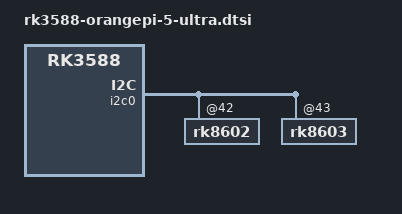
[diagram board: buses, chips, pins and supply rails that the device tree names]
// SPDX-License-Identifier: (GPL-2.0+ OR MIT)
/*
 * PATCHED DTSI – Orange Pi 5 Ultra
 * File: rk3588-orangepi-5-ultra-r06.dtsi
 *
 * Revision note:
 * r06 - keep OPi5U big-cluster 2400 MHz released and overvolted to 1.05 V
 *       only at the final 2400 MHz OPP
 *     - relax big-cluster OPP consumer max ceilings from 1.00 V to 1.05 V
 *       across cluster1 and cluster2 standard OPP tables so transitions from
 *       the 2400 MHz 1.05 V step do not fail on the shared cpu/mem rail vote
 *     - keep lower OPP target/min voltages unchanged
 *     - patch rk8602/rk8603 under &i2c0 to avoid forward-label issues
 *
 * Notes:
 * - This is board-local for OPi5U in FriendlyElec AOSP 14 tree.
 * - Lower big-cluster OPPs are NOT overvolted in target/min terms.
 * - Only their allowed max ceiling is relaxed to match the rail ceiling.
 */

&i2c0 {
	rk8602@42 {
		regulator-max-microvolt = <1050000>;
	};

	rk8603@43 {
		regulator-max-microvolt = <1050000>;
	};
};

&cluster1_opp_table {
	opp-408000000 {
		opp-microvolt = <675000 675000 1050000>,
			       <675000 675000 1050000>;
	};
	opp-600000000 {
		opp-microvolt = <675000 675000 1050000>,
			       <675000 675000 1050000>;
	};
	opp-816000000 {
		opp-microvolt = <675000 675000 1050000>,
			       <675000 675000 1050000>;
	};
	opp-1008000000 {
		opp-microvolt = <675000 675000 1050000>,
			       <675000 675000 1050000>;
	};
	opp-1200000000 {
		opp-microvolt = <675000 675000 1050000>,
			       <675000 675000 1050000>;
	};
	opp-1416000000 {
		opp-microvolt = <725000 725000 1050000>,
			       <725000 725000 1050000>;
		opp-microvolt-L2 = <712500 712500 1050000>,
			       <712500 712500 1050000>;
		opp-microvolt-L3 = <700000 700000 1050000>,
			       <700000 700000 1050000>;
		opp-microvolt-L4 = <700000 700000 1050000>,
			       <700000 700000 1050000>;
		opp-microvolt-L5 = <687500 687500 1050000>,
			       <687500 687500 1050000>;
		opp-microvolt-L6 = <675000 675000 1050000>,
			       <675000 675000 1050000>;
		opp-microvolt-L7 = <675000 675000 1050000>,
			       <675000 675000 1050000>;
	};
	opp-1608000000 {
		opp-microvolt = <762500 762500 1050000>,
			       <762500 762500 1050000>;
		opp-microvolt-L2 = <750000 750000 1050000>,
			       <750000 750000 1050000>;
		opp-microvolt-L3 = <737500 737500 1050000>,
			       <737500 737500 1050000>;
		opp-microvolt-L4 = <725000 725000 1050000>,
			       <725000 725000 1050000>;
		opp-microvolt-L5 = <712500 712500 1050000>,
			       <712500 712500 1050000>;
		opp-microvolt-L6 = <700000 700000 1050000>,
			       <700000 700000 1050000>;
		opp-microvolt-L7 = <700000 700000 1050000>,
			       <700000 700000 1050000>;
	};
	opp-1800000000 {
		opp-microvolt = <850000 850000 1050000>,
			       <850000 850000 1050000>;
		opp-microvolt-L1 = <837500 837500 1050000>,
			       <837500 837500 1050000>;
		opp-microvolt-L2 = <825000 825000 1050000>,
			       <825000 825000 1050000>;
		opp-microvolt-L3 = <812500 812500 1050000>,
			       <812500 812500 1050000>;
		opp-microvolt-L4 = <800000 800000 1050000>,
			       <800000 800000 1050000>;
		opp-microvolt-L5 = <787500 787500 1050000>,
			       <787500 787500 1050000>;
		opp-microvolt-L6 = <775000 775000 1050000>,
			       <775000 775000 1050000>;
		opp-microvolt-L7 = <762500 762500 1050000>,
			       <762500 762500 1050000>;
	};
	opp-2016000000 {
		opp-microvolt = <925000 925000 1050000>,
			       <925000 925000 1050000>;
		opp-microvolt-L1 = <912500 912500 1050000>,
			       <912500 912500 1050000>;
		opp-microvolt-L2 = <900000 900000 1050000>,
			       <900000 900000 1050000>;
		opp-microvolt-L3 = <887500 887500 1050000>,
			       <887500 887500 1050000>;
		opp-microvolt-L4 = <875000 875000 1050000>,
			       <875000 875000 1050000>;
		opp-microvolt-L5 = <862500 862500 1050000>,
			       <862500 862500 1050000>;
		opp-microvolt-L6 = <850000 850000 1050000>,
			       <850000 850000 1050000>;
		opp-microvolt-L7 = <837500 837500 1050000>,
			       <837500 837500 1050000>;
	};
	opp-2208000000 {
		opp-microvolt = <987500 987500 1050000>,
			       <987500 987500 1050000>;
		opp-microvolt-L1 = <975000 975000 1050000>,
			       <975000 975000 1050000>;
		opp-microvolt-L2 = <962500 962500 1050000>,
			       <962500 962500 1050000>;
		opp-microvolt-L3 = <950000 950000 1050000>,
			       <950000 950000 1050000>;
		opp-microvolt-L4 = <962500 962500 1050000>,
			       <962500 962500 1050000>;
		opp-microvolt-L5 = <950000 950000 1050000>,
			       <950000 950000 1050000>;
		opp-microvolt-L6 = <925000 925000 1050000>,
			       <925000 925000 1050000>;
		opp-microvolt-L7 = <912500 912500 1050000>,
			       <912500 912500 1050000>;
	};
	opp-2256000000 {
		opp-microvolt = <1000000 1000000 1050000>,
			       <1000000 1000000 1050000>;
	};
	opp-2304000000 {
		opp-microvolt = <1000000 1000000 1050000>,
			       <1000000 1000000 1050000>;
	};
	opp-2352000000 {
		opp-microvolt = <1000000 1000000 1050000>,
			       <1000000 1000000 1050000>;
	};
	opp-2400000000 {
		opp-supported-hw = <0xe9 0x48>;
		opp-microvolt = <1050000 1050000 1050000>,
			       <1050000 1050000 1050000>;
	};
};

&cluster2_opp_table {
	opp-408000000 {
		opp-microvolt = <675000 675000 1050000>,
			       <675000 675000 1050000>;
	};
	opp-600000000 {
		opp-microvolt = <675000 675000 1050000>,
			       <675000 675000 1050000>;
	};
	opp-816000000 {
		opp-microvolt = <675000 675000 1050000>,
			       <675000 675000 1050000>;
	};
	opp-1008000000 {
		opp-microvolt = <675000 675000 1050000>,
			       <675000 675000 1050000>;
	};
	opp-1200000000 {
		opp-microvolt = <675000 675000 1050000>,
			       <675000 675000 1050000>;
	};
	opp-1416000000 {
		opp-microvolt = <725000 725000 1050000>,
			       <725000 725000 1050000>;
		opp-microvolt-L2 = <712500 712500 1050000>,
			       <712500 712500 1050000>;
		opp-microvolt-L3 = <700000 700000 1050000>,
			       <700000 700000 1050000>;
		opp-microvolt-L4 = <700000 700000 1050000>,
			       <700000 700000 1050000>;
		opp-microvolt-L5 = <687500 687500 1050000>,
			       <687500 687500 1050000>;
		opp-microvolt-L6 = <675000 675000 1050000>,
			       <675000 675000 1050000>;
		opp-microvolt-L7 = <675000 675000 1050000>,
			       <675000 675000 1050000>;
	};
	opp-1608000000 {
		opp-microvolt = <762500 762500 1050000>,
			       <762500 762500 1050000>;
		opp-microvolt-L2 = <750000 750000 1050000>,
			       <750000 750000 1050000>;
		opp-microvolt-L3 = <737500 737500 1050000>,
			       <737500 737500 1050000>;
		opp-microvolt-L4 = <725000 725000 1050000>,
			       <725000 725000 1050000>;
		opp-microvolt-L5 = <712500 712500 1050000>,
			       <712500 712500 1050000>;
		opp-microvolt-L6 = <700000 700000 1050000>,
			       <700000 700000 1050000>;
		opp-microvolt-L7 = <700000 700000 1050000>,
			       <700000 700000 1050000>;
	};
	opp-1800000000 {
		opp-microvolt = <850000 850000 1050000>,
			       <850000 850000 1050000>;
		opp-microvolt-L1 = <837500 837500 1050000>,
			       <837500 837500 1050000>;
		opp-microvolt-L2 = <825000 825000 1050000>,
			       <825000 825000 1050000>;
		opp-microvolt-L3 = <812500 812500 1050000>,
			       <812500 812500 1050000>;
		opp-microvolt-L4 = <800000 800000 1050000>,
			       <800000 800000 1050000>;
		opp-microvolt-L5 = <787500 787500 1050000>,
			       <787500 787500 1050000>;
		opp-microvolt-L6 = <775000 775000 1050000>,
			       <775000 775000 1050000>;
		opp-microvolt-L7 = <762500 762500 1050000>,
			       <762500 762500 1050000>;
	};
	opp-2016000000 {
		opp-microvolt = <925000 925000 1050000>,
			       <925000 925000 1050000>;
		opp-microvolt-L1 = <912500 912500 1050000>,
			       <912500 912500 1050000>;
		opp-microvolt-L2 = <900000 900000 1050000>,
			       <900000 900000 1050000>;
		opp-microvolt-L3 = <887500 887500 1050000>,
			       <887500 887500 1050000>;
		opp-microvolt-L4 = <875000 875000 1050000>,
			       <875000 875000 1050000>;
		opp-microvolt-L5 = <862500 862500 1050000>,
			       <862500 862500 1050000>;
		opp-microvolt-L6 = <850000 850000 1050000>,
			       <850000 850000 1050000>;
		opp-microvolt-L7 = <837500 837500 1050000>,
			       <837500 837500 1050000>;
	};
	opp-2208000000 {
		opp-microvolt = <987500 987500 1050000>,
			       <987500 987500 1050000>;
		opp-microvolt-L3 = <975000 975000 1050000>,
			       <975000 975000 1050000>;
		opp-microvolt-L4 = <962500 962500 1050000>,
			       <962500 962500 1050000>;
		opp-microvolt-L5 = <950000 950000 1050000>,
			       <950000 950000 1050000>;
		opp-microvolt-L6 = <925000 925000 1050000>,
			       <925000 925000 1050000>;
		opp-microvolt-L7 = <912500 912500 1050000>,
			       <912500 912500 1050000>;
	};
	opp-2256000000 {
		opp-microvolt = <1000000 1000000 1050000>,
			       <1000000 1000000 1050000>;
	};
	opp-2304000000 {
		opp-microvolt = <1000000 1000000 1050000>,
			       <1000000 1000000 1050000>;
	};
	opp-2352000000 {
		opp-microvolt = <1000000 1000000 1050000>,
			       <1000000 1000000 1050000>;
	};
	opp-2400000000 {
		opp-supported-hw = <0xe9 0x48>;
		opp-microvolt = <1050000 1050000 1050000>,
			       <1050000 1050000 1050000>;
	};
};
